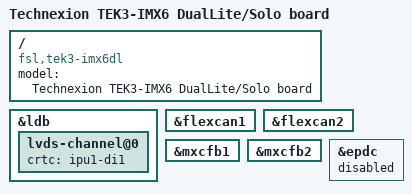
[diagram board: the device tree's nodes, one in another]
/*
 * Copyright 2015 Technexion Ltd.
 *
 * Author: Richard Hu <richard.hu@technexion.com>
 *
 * This program is free software; you can redistribute it and/or modify
 * it under the terms of the GNU General Public License version 2 as
 * published by the Free Software Foundation.
 *
 */
/dts-v1/;

#include <dt-bindings/interrupt-controller/irq.h>
#include "imx6dl.dtsi"
#include "imx6qdl-tek3.dtsi"

/ {
	model = "Technexion TEK3-IMX6 DualLite/Solo board";
	compatible = "fsl,tek3-imx6dl", "fsl,imx6dl";
};

&ldb {
	lvds-channel@0 {
		crtc = "ipu1-di1";
	};
};

&flexcan1{
	status = "okay";
};

&flexcan2{
	status = "okay";
};

&mxcfb1 {
	status = "okay";
};

&mxcfb2 {
	status = "okay";
};

#if 0
&mxcfb3 {
	status = "okay";
};

&mxcfb4 {
	status = "okay";
};
#endif

&epdc {
	status = "disabled";
};


